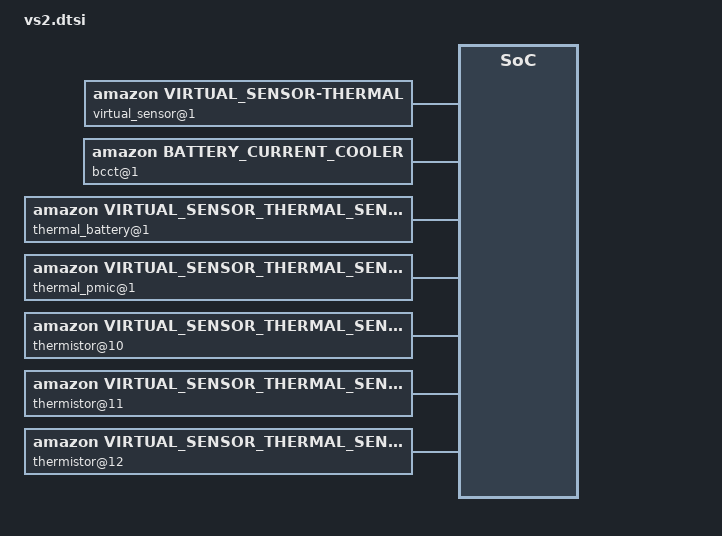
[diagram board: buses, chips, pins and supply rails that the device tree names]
/*
 * Copyright (c) 2017 MediaTek Inc.
 * Author: Keene Tsai <keene.tsai@mediatek.com>
 *
 * This program is free software; you can redistribute it and/or modify
 * it under the terms of the GNU General Public License version 2 as
 * published by the Free Software Foundation.
 *
 * This program is distributed in the hope that it will be useful,
 * MERCHANTABILITY or FITNESS FOR A PARTICULAR PURPOSE.  See the
 * GNU General Public License for more details.
 */
vs2_wire: vs2_wire {
	compatible = "amazon,vs2_wire", "simple-bus";
	status = "okay";

	/*
	 * Virtual sensor
	 * select_device: Decide to register which thermal_zone device
	 * 0: register to thermal_zone9, 1: register to thermal_zone10
	 */
	virtual_sensor@1{
		compatible = "amazon,virtual_sensor-thermal";
		dev_id = <1>;
		num_trips = <9>;
		mode = <0>;
		polling_delay = <3000>;
		governor_name = "virtual_sensor";
		num_tbps = <3>;
		temp = <48000 48500 49000 50000 53000 56000 57000 58000 60000 60000 60000 60000>;
		type = <0 0 0 0 0 0 0 0 3 3 3 3>;
		hyst = <3000 0 0 0 3000 0 0 3000 0 0 0 0>;
		num_cdevs = <2>;
		cdev_names = "thermal_budget1","bcct1";
	};
	/* Battery Current Cooler */
	bcct@1 {
		compatible = "amazon,battery_current_cooler";
		type = "bcct1";
		state = <0>;
		max_state = <12>;
		level = <320001>;
		thermal_cooler_id = <0>;
		levels = <100000 100000 100000 10000 10000 10000 10000 10000 10000 10000 10000 10000>;
	};

	/* Thermal_budget Cooler */
	thermal_budget@1 {
		compatible = "amazon,thermal_budget_cooler";
		type = "thermal_budget1";
		state = <0>;
		max_state = <12>;
		level = <4600>;
		thermal_cooler_id = <2>;
		levels = <941 846 707 625 553 441 372 235 235 235 235 235>;
	};
	/*Virtual sensor battery*/
	thermal_battery@1{
		compatible = "amazon,virtual_sensor_thermal_sensor";
		thermal_sensor,offset = <12000>;
		thermal_sensor,offset_invert = <0>;
		thermal_sensor,alpha = <13>;
		thermal_sensor,weight = <269>;
		thermal_sensor,weight_invert = <0>;
		thermal_sensor_id = <1>;
		aux_channel_num = <0>;
		select_device = <1>;
	};
	/*Virtual sensor pmic*/
	thermal_pmic@1{
		compatible = "amazon,virtual_sensor_thermal_sensor";
		thermal_sensor,offset = <44700>;
		thermal_sensor,alpha = <1000>;
		thermal_sensor,weight = <29>;
		thermal_sensor,weight_invert = <0>;
		thermal_sensor,offset_invert = <0>;
		thermal_sensor_id = <3>;
		aux_channel_num = <0>;
		select_device = <1>;
	};
	/* Virtual sensor thermistor */
	thermistor@10 {
		compatible = "amazon,virtual_sensor_thermal_sensor";
		thermal_sensor,offset = <19300>;
		thermal_sensor,offset_invert = <1>;
		thermal_sensor,alpha = <1000>;
		thermal_sensor,weight = <460>;
		thermal_sensor,weight_invert = <0>;
		thermal_sensor_id = <5>;
		aux_channel_num = <0>;
		select_device = <1>;
	};
	thermistor@11 {
		compatible = "amazon,virtual_sensor_thermal_sensor";
		thermal_sensor,offset = <47300>;
		thermal_sensor,offset_invert = <0>;
		thermal_sensor,alpha = <302>;
		thermal_sensor,weight = <0>;
		thermal_sensor,weight_invert = <0>;
		thermal_sensor_id = <5>;
		aux_channel_num = <1>;
		select_device = <1>;
	};
	thermistor@12 {
		compatible = "amazon,virtual_sensor_thermal_sensor";
		thermal_sensor,offset = <15100>;
		thermal_sensor,offset_invert = <0>;
		thermal_sensor,alpha = <742>;
		thermal_sensor,weight = <313>;
		thermal_sensor,weight_invert = <0>;
		thermal_sensor_id = <5>;
		aux_channel_num = <2>;
		select_device = <1>;
	};
};

vs2_wpc: vs2_wpc {
	compatible = "amazon,vs2_wpc", "simple-bus";
	status = "disabled";

	/*
	 * Virtual sensor
	 * select_device: Decide to register which thermal_zone device
	 * 0: register to thermal_zone9, 1: register to thermal_zone10
	 */
	virtual_sensor@1{
		compatible = "amazon,virtual_sensor-thermal";
		dev_id = <1>;
		num_trips = <9>;
		mode = <0>;
		polling_delay = <3000>;
		governor_name = "virtual_sensor";
		num_tbps = <3>;
		temp = <48000 48500 49000 50000 53000 56000 57000 58000 60000 60000 60000 60000>;
		type = <0 0 0 0 0 0 0 0 3 3 3 3>;
		hyst = <3000 0 0 0 3000 0 0 3000 0 0 0 0>;
		num_cdevs = <2>;
		cdev_names = "thermal_budget1","bcct1";
	};
	/* Battery Current Cooler */
	bcct@1 {
		compatible = "amazon,battery_current_cooler";
		type = "bcct1";
		state = <0>;
		max_state = <12>;
		level = <320001>;
		thermal_cooler_id = <0>;
		levels = <100000 100000 100000 10000 10000 10000 10000 10000 10000 10000 10000 10000>;
	};

	/* Thermal_budget Cooler */
	thermal_budget@1 {
		compatible = "amazon,thermal_budget_cooler";
		type = "thermal_budget1";
		state = <0>;
		max_state = <12>;
		level = <4600>;
		thermal_cooler_id = <2>;
		levels = <941 846 707 625 553 441 372 235 235 235 235 235>;
	};
	/*Virtual sensor battery*/
	thermal_battery@1{
		compatible = "amazon,virtual_sensor_thermal_sensor";
		thermal_sensor,offset = <2390>;
		thermal_sensor,offset_invert = <0>;
		thermal_sensor,alpha = <1000>;
		thermal_sensor,weight = <414>;
		thermal_sensor,weight_invert = <0>;
		thermal_sensor_id = <1>;
		aux_channel_num = <0>;
		select_device = <1>;
	};
	/*Virtual sensor pmic*/
	thermal_pmic@1{
		compatible = "amazon,virtual_sensor_thermal_sensor";
		thermal_sensor,offset = <34900>;
		thermal_sensor,alpha = <1000>;
		thermal_sensor,weight = <73>;
		thermal_sensor,weight_invert = <0>;
		thermal_sensor,offset_invert = <0>;
		thermal_sensor_id = <3>;
		aux_channel_num = <0>;
		select_device = <1>;
	};
	/* Virtual sensor thermistor */
	thermistor@10 {
		compatible = "amazon,virtual_sensor_thermal_sensor";
		thermal_sensor,offset = <51000>;
		thermal_sensor,offset_invert = <0>;
		thermal_sensor,alpha = <1>;
		thermal_sensor,weight = <0>;
		thermal_sensor,weight_invert = <0>;
		thermal_sensor_id = <5>;
		aux_channel_num = <0>;
		select_device = <1>;
	};
	thermistor@11 {
		compatible = "amazon,virtual_sensor_thermal_sensor";
		thermal_sensor,offset = <31100>;
		thermal_sensor,offset_invert = <0>;
		thermal_sensor,alpha = <1000>;
		thermal_sensor,weight = <120>;
		thermal_sensor,weight_invert = <0>;
		thermal_sensor_id = <5>;
		aux_channel_num = <1>;
		select_device = <1>;
	};
	thermistor@12 {
		compatible = "amazon,virtual_sensor_thermal_sensor";
		thermal_sensor,offset = <14800>;
		thermal_sensor,offset_invert = <1>;
		thermal_sensor,alpha = <893>;
		thermal_sensor,weight = <437>;
		thermal_sensor,weight_invert = <0>;
		thermal_sensor_id = <5>;
		aux_channel_num = <2>;
		select_device = <1>;
	};
};
